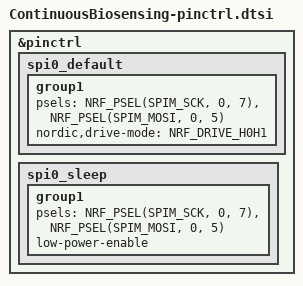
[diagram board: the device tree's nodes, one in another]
&pinctrl {
    spi0_default: spi0_default {
        group1 {
            psels = <NRF_PSEL(SPIM_SCK,  0, 7)>,
                    <NRF_PSEL(SPIM_MOSI, 0, 5)>;
            nordic,drive-mode = <NRF_DRIVE_H0H1>;
        };
    };
    spi0_sleep: spi0_sleep {
        group1 {
           psels = <NRF_PSEL(SPIM_SCK,  0, 7)>,
                    <NRF_PSEL(SPIM_MOSI, 0, 5)>;
            low-power-enable;
       };
    };
};
